# UART0 register map
Vendor: Texas Instruments
Peripheral module from a debugger description file (folder UCD3138R064RSM).
Registers are 32-bit, access per field, no defined reset value unless marked. A register's access mark holds for its fields unless they carry their own. Offsets are as the file gives them; lines under a group give offsets from that group; [hi:lo] are bit positions; {n}, {i} and the like mark numbered series; 'fields as' and 'values as' point back to an identical list; <NAME> marks a mode.

## UART0
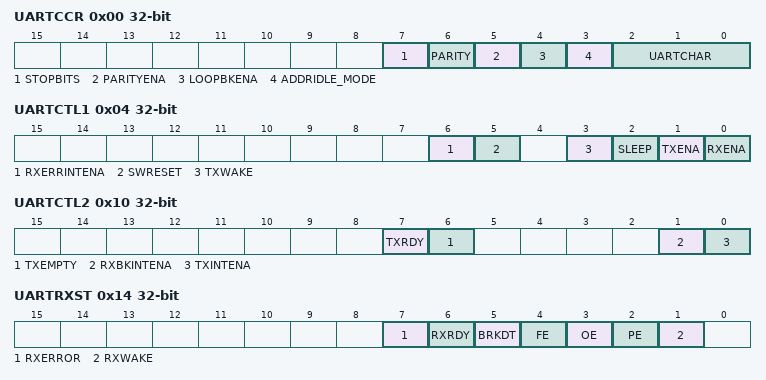
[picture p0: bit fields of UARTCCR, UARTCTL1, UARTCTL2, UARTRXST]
0x00 UARTCCR — UARTCCR defines the character format, protocol, and communications mode used by the UART.
  [7] STOPBITS rw — UART number of stop bits. #br#This bit specifies the number of stop bits transmitted. The receiver checks for only one stop bit.
    0=STOPBITS_ONE (One stop bit); 1=STOPBITS_TWO (Two stop bits)
  [6] PARITY rw — UART parity odd/even selection. #br#If the PARITY ENABLE bit (UARTCCR, bit 5) is set, PARITY (bit 6) designates odd or even parity (odd or even number of bits with the value of 1 in both transmitted and received characters).
    0=PARITY_ODD (Odd parity); 1=PARITY_EVEN (Even parity)
  [5] PARITYENA rw — UART parity enable. #br#This bit enables or disables the parity function. If the UART is in the addressbit multiprocessor mode (set using bit 3 of this register), the address bit is included in the parity calculation (if parity is enabled). For characters of less than eight bits, the remaining unused bits should be masked out of the parity calculation.
    0=PARITYENA_DISABLE (Parity disabled; no parity bit is generated during transmission or is expected during reception); 1=PARITYENA_ENABLE (Parity is enabled)
  [4] LOOPBKENA rw — Loop Back test mode enable. #br#This bit enables the Loop Back test mode where the Tx pin is internally connected to the Rx pin.
    0=LOOPBKENA_DISABLE (Loop Back test mode disabled); 1=LOOPBKENA_ENABLE (Loop Back test mode enabled)
  [3] ADDRIDLE_MODE rw — UART multiprocessor mode control bit. #br# #br#This bit selects one of the multiprocessor protocols.Multiprocessor communication is different from the other communication modes because it uses SLEEP and TXWAKE functions (bits UARTCTL1, bit 2 and UARTCTL1, bit 3, respectively). The idle-line mode is usually used for normal communications because the address-bit mode #br#adds an extra bit to the frame. The idle-line mode does not add this extra bit and is compatible with RS-232 type communications.
    0=ADDRIDLE_MODE_IDLE (Idle-line mode protocol selected); 1=ADDRIDLE_MODE_ADDRBIT (Address-bit mode protocol selected)
  [2:0] UARTCHAR rw — Character-length control bits 2-0. #br# #br#These bits select the UART character length from one to eight bits. Characters of less than eight bits are right-justified in UARTRXBUF and UARTRXEMU and are padded with leading zeros in UARTRXBUF. UARTTXBUF doesn't need to be padded with leading zeros.
    {v}=UARTCHAR_LENGTH_{v+1} (v=0..7)
0x04 UARTCTL1 — UARTCTL1 controls the receiver/transmitter enable, TXWAKE and SLEEP functions, and the UART software reset.
  [6] RXERRINTENA rw — UART receive error interrupt enable. #br#Setting this bit enables an interrupt if the RX ERROR bit (UARTRXST, bit 7) becomes set because of errors occurring.
    0=RXERRINTENA_DISABLE (Receive error interrupt disabled); 1=RXERRINTENA_ENABLE (Receive error interrupt enabled)
  [5] SWRESET rw — UART software reset (active low). #br#Writing a 0 to this bit initializes the UART state machines and operating flags (registers UARTCTL2 and UARTRXST) to the reset condition. This reset will not reset the FIFO pointers or flush out the data in TX/RX FIFO. If you need to clear the FIFO then perform SWRESET + TXFFINT + RXFFINT or refer to a channel reset UARTFFTX[UARTRST]. #br# #br#The SW RESET bit does not affect any of the configuration bits. All affected logic is held in the specified reset state until a 1 is written to SW RESET (the bit values following a reset are shown beneath each register diagram in this section). Thus, after a system reset, re-enable the UART by writing a 1 to this bit. Clear this bit after a receiver break detect (BRKDT flag, bit UARTRXST, bit 5). #br# #br#SW RESET affects the operating flags of the UART, but it neither affects the configuration bits nor restores the reset values. Once SW RESET is asserted, the flags are frozen until the bit is deasserted. #br#The affected flags are as follows: #br# #br#Value After SW UART Flag Register Bit #br#RESET #br#1 TXRDY UARTCTL2, bit 7 #br#1 TX EMPTY UARTCTL2, bit 6 #br#0 RXWAKE UARTRXST, bit 1 #br#0 PE UARTRXST, bit 2 #br#0 OE UARTRXST, bit 3 #br#0 FE UARTRXST, bit 4 #br#0 BRKDT UARTRXST, bit 5 #br#0 RXRDY UARTRXST, bit 6 #br#0 RX ERROR UARTRXST, bit 7
    0=SWRESET_RESET (Writing a 0 to this bit initializes the UART state machines and operating flags (registers UARTCTL2 and UARTRXST) to the reset condition.); 1=SWRESET_REEN (After a system reset, re-enable the UART by writing a 1 to this bit. There is no time requirement to meet before writing a one to this bit after writing a zero.)
  [3] TXWAKE rw — UART transmitter wake-up method select. #br# #br#The TXWAKE bit controls selection of the data-transmit feature, depending on which transmit mode (idle-line or address-bit) is specified at the ADDR/IDLE MODE bit (UARTCCR, bit 3)
    0=TXWAKE_NOSELECT (Transmit feature is not selected. In idle-line mode: write a 1 to TXWAKE, then write data to register UARTTXBUF to generate an idle period of 11 data bits In address-bit mode: write a 1 to TXWAKE, then write data to UARTTXBUF to set the address bit for that frame to 1); 1=TXWAKE_SELECT (Transmit feature selected is dependent on the mode, idle-line or address-bit: TXWAKE is not cleared by the SW RESET bit (UARTCTL1, bit 5); it is cleared by a system reset or the transfer of TXWAKE to the WUT flag.)
  [2] SLEEP rw — UART sleep. #br#The TXWAKE bit controls selection of the data-transmit feature, depending on which transmit mode (idle-line or address-bit) is specified at the ADDR/IDLE MODE bit (UARTCCR, bit 3). In a multiprocessor configuration, this bit controls the receiver sleep function. Clearing this bit brings the UART out of the sleep mode. #br# #br#The receiver still operates when the SLEEP bit is set; however, operation does not update the receiver buffer ready bit (UARTRXST, bit 6, RXRDY) or the error status bits (UARTRXST, bit 5-2: BRKDT, FE, OE, and PE) unless the address byte is detected. SLEEP is not cleared when the address byte is detected.
    0=SLEEP_DISABLE (Sleep mode disabled); 1=SLEEP_ENABLE (Sleep mode enabled)
  [1] TXENA rw — UART transmitter enable. #br#Data is transmitted through the UARTTXD pin only when TXENA is set. If reset, transmission is halted but only after all data previously written to UARTTXBUF has been sent. Data written into UARTTXBUF when TXENA is disabled will not be transmitted even if the TXENA is enabled later.
    0=TXENA_DISABLE (Transmitter disabled); 1=TXENA_ENABLE (Transmitter enabled)
  [0] RXENA rw — UART receiver enable. #br#Data is received on the UARTRXD pin and is sent to the receiver shift register and then the receiver buffers. This bit enables or disables the receiver (transfer to the buffers). #br#Clearing RXENA stops received characters from being transferred to the two receiver buffers and also stops the generation of receiver interrupts. However, this will not stop RX errors from triggering interrupts. To disable interrupts from RX errors use the RXERRINTENA bit. To stop propagation of the BRKDT interrupt use the RXBKINTENA bit. #br# #br#The receiver shift register can continue to assemble characters even while RXENA is cleared. Thus, if RXENA is set during the reception of a character, the complete character will be transferred into the receiver buffer registers, UARTRXEMU and UARTRXBUF.
    0=RXENA_DISABLE (Prevent received characters from transfer into the UARTRXEMU and UARTRXBUF receiver buffers); 1=RXENA_ENABLE (Send received characters to UARTRXEMU and UARTRXBUF)
0x08 UARTHBAUD — The values in UARTHBAUD and UARTLBAUD specify the baud rate for the UART.
  [7:0] BAUD rw — UART 16-bit baud selection Registers UARTHBAUD (MSbyte). #br# #br#The internally-generated serial clock is determined by the low speed peripheral clock (LSPCLK) signal and the two baud-select registers. The UART uses the 16-bit value of these registers to select one of 64K serial clock rates for the communication modes. #br# #br#BRR = (UARTHBAUD << 8) + (UARTLBAUD) #br# #br#The UART baud rate is calculated using the following equation: #br# #br#UART Asynchronous Baud = LSPCLK / ((BRR + 1) *8) #br# #br#Alternatively, #br# #br#BRR = LSPCLK / (UART Asynchronous Baud * 8) - 1 #br# #br#Note that the above formulas are applicable only when 0 < BRR < 65536. If BRR = 0, then #br# #br#UART Asynchronous Baud = LSPCLK / 16 #br# #br#Where: BRR = the 16-bit value (in decimal) in the baud-select registers
0x0C UARTLBAUD — The values in UARTHBAUD and UARTLBAUD specify the baud rate for the UART.
  [7:0] BAUD rw — See UARTHBAUD Detailed Description
0x10 UARTCTL2 — UARTCTL2 enables the receive-ready, break-detect, and transmit-ready interrupts as well as transmitter-ready and -empty flags.
  [7] TXRDY ro — Transmitter buffer register ready flag. #br#When set, this bit indicates that the transmit data buffer register, UARTTXBUF, is ready to receive another character. Writing data to the UARTTXBUF automatically clears this bit. When set, this flag asserts a transmitter interrupt request if the interrupt-enable bit, TX INT ENA (UARTCTL2.0), is also set. TXRDY is set to 1 by enabling the SW RESET bit (UARTCTL1.5) or by a system reset.
    0=TXRDY_FULL (UARTTXBUF is full); 1=TXRDY_READY (UARTTXBUF is ready to receive the next character)
  [6] TXEMPTY ro — Transmitter empty flag. #br#This flag's value indicates the contents of the transmitter's buffer register (UARTTXBUF) and shift register (TXSHF). An active SW RESET (UARTCTL1.5), or a system reset, sets this bit. This bit does not cause an interrupt request.
    0=TXEMPTY_LOAD (Transmitter buffer or shift register or both are loaded with data); 1=TXEMPTY_EMPTY (Transmitter buffer and shift registers are both empty)
  [1] RXBKINTENA rw — Receiver-buffer/break interrupt enable. #br#This bit controls the interrupt request caused by either the RXRDY flag or the BRKDT flag (bits UARTRXST.6 and .5) being set. However, RX/BK INT ENA does not prevent the setting of these flags.
    0=RXBKINTENA_DISABLE (Disable RXRDY/BRKDT interrupt); 1=RXBKINTENA_ENABLE (Enable RXRDY/BRKDT interrupt)
  [0] TXINTENA rw — UARTTXBUF-register interrupt enable. #br#This bit controls the interrupt request caused by the setting of TXRDY flag bit (UARTCTL2.7). However, it does not prevent the TXRDY flag from being set (which indicates UARTTXBUF is ready to receive another character). #br# #br#0 Disable TXRDY interrupt #br#1 Enable TXRDY interrupt. #br# #br#In non-FIFO mode, a dummy (or a valid) data has to be written to UARTTXBUF for the first transmit interrupt to occur. This is the case when you enable the transmit interrupt for the first time and also when you re-enable (disable and then enable) the transmit interrupt. If TXINTENA is enabled after writing the data to UARTTXBUF, it will not generate an interrupt.
    0=TXINTENA_DISABLE (Disable TXRDY interrupt); 1=TXINTENA_ENABLE (Enable TXRDY interrupt)
0x14 UARTRXST ro — UARTRXST contains seven bits that are receiver status flags (two of which can generate interrupt requests). Each time a complete character is transferred to the receiver buffers (UARTRXEMU and UARTRXBUF), the status flags are updated.
  [7] RXERROR — UART receiver error flag. #br#The RX ERROR flag indicates that one of the error flags in the receiver status register is set. RX ERROR is a logical OR of the break detect, framing error, overrun, and parity error enable flags (bits 5-2: BRKDT, FE, OE, and PE). #br#A 1 on this bit will cause an interrupt if the RX ERR INT ENA bit (UARTCTL1.6) is set. This bit can be used for fast error-condition checking during the interrupt service routine. This error flag cannot be cleared directly; it is cleared by an active SW RESET, channel reset (UARTRST), or by a system reset. #br# #br#Note: UART Module Interrupt Reaction Time - Occasional BRKDT or other errors such as FE/PE being triggered could occur if there are tight timings occurring in the application. #br# #br#Interrupts are not triggered until approximately 7/8 of the stop bit has been detected (~0.875 bit time). Actual value of this delay before ISR entry is: ((7*BAUD_CLK_PERIOD)/8+3*SYSCLK_PERIOD). #br# #br#The UART will not begin reading additional bits/characters until the RX ISR completes so it is critical to complete the ISR before the next byte's start bit begins. This leaves approximately 1/8 bit time (~0.125 bit time) to complete the entire ISR, regardless of interrupt cause. #br# #br#If the ISR is not completed before the beginning of the next start bit (before the RX line goes low again), the UART module will begin reading the start bit late in the wrong location and therefore may read all bits incorrectly until the next correctly aligned start bit (when ISR has sufficient time to process before a start bit again). #br# #br#Recommended methods for avoiding errors (to accommodate for the 0.875 bit time required for ISR to begin): #br#1. Keep the RX ISR short. The RX ISR should only be used to move data in the FIFO/buffer into memory where it can be processed in another, less time-critical function. #br#2. Avoid excessive nesting of other interrupts within the UART RX ISR. Do not allow the nesting to delay UART RX ISR completion past the ~0.125 bit time window allowed. #br#3. If additional time (more than the ~0.125 bit time) is required, delay can be added in the other device's firmware before transmitting additional data to the C2000 device's UART RX pin. Delays can be added to the other device as follows: #br# A. Sending bytes with 2 stop bits to the C2000 device provides ~1.125 bit time of processing time for C2000 RX ISR to complete. #br# B. Adding manual delay in the firmware of the other device transmitting to the C2000 device after every BYTE transmitted will provide (delay + ~0.125 bit time) processing time for the C2000 RX ISR to complete. #br# C. Adding manual delay in the firmware of the other device transmitting to the C2000 device after every C2000 RX INTERRUPT occurs will provide (delay + ~0.125 bit time) processing time for the C2000 RX ISR to complete. This is more difficult to implement as it requires the other device to predict when its transmitted data will trigger an RX interrupt on the C2000 device. Examples of things that can trigger an RX interrupt are RX-FIFO level being reached, BRKDT being sent, RXERROR occurring, etc.
    0=RXERROR_NO_ERR (No error flags set); 1=RXERROR_SET_ERR (Error flag(s) set)
  [6] RXRDY — UART receiver-ready flag. #br#When a new character is ready to be read from the UARTRXBUF register, the receiver sets this bit, and a receiver interrupt is generated if the RX/BK INT ENA bit (UARTCTL2.1) is a 1. RXRDY is cleared by a reading of the UARTRXBUF register, by an active SW RESET, channel reset (UARTRST), or by a system reset.
    0=RXRDY_NO_CHAR (No new character in UARTRXBUF); 1=RXRDY_READY (Character ready to be read from UARTRXBUF)
  [5] BRKDT — UART break-detect flag. #br#The UART sets this bit when a break condition occurs. A break condition occurs when the UART receiver data line (UARTRXD) remains continuously low for at least 9.625 bits, beginning after a missing first stop bit. If the UARTRX line goes high at any point during the 9.625 bits then the UART will not flag a break detect. In order to trigger the first stop bit missed, the typical method is to hold the RX line low for 1 start bit, 8 data bits, 1 optional address bit, 1 optional parity bit, 1 stop bit, and 9.625 bits of additional time held low. This is a total of 19.625 (no parity/address bit), 20.625 (either parity or address bit), or 21.625 (both parity and address bit) bit times. #br# #br#To instead detect a "break seq" or "break sequence" of 11 bits of low voltage level (0), ISR code can use the following combination of flags and received data: FE==1 && PE==1 && UARTRXBUF.SAR (received character)==0x00. This assumes parity enabled and odd parity set. With even parity, PE==0 instead. The detection of 11 bits of low/0 can be reduced to 10 bits of low if no parity bit is used (then PE flag does not matter to detect the sequence). #br# #br#The occurrence of a break causes a receiver interrupt to be generated if the RX/BK INT ENA bit is a 1, but it does not cause the receiver buffer to be loaded. #br# #br#A BRKDT interrupt can occur even if the receiver SLEEP bit is set to 1. #br# #br#BRKDT is cleared by an active SW RESET, UARTRST bit, or by a system reset. It is not cleared by receipt of a character after the break is detected. #br# #br#If Break Detect (BRKDT) is set, then RXRDY won't be set and there will be no further interrupts after the first interrupt where there is an error detected if a SW reset, channel reset, or system reset is not performed. In order to receive more characters, the UART must be reset by toggling the SW RESET bit, channel reset (UARTRST), or by a system reset. #br# #br#NOTE: If your system is susceptible to break detects, ensure that you have a pull-up resistor on the UART-RX pin to provide proper return-to-high signal behavior and noise immunity. #br# #br#NOTE: To monitor a break detect, place an oscilloscope on the C2000 UART-RX line and monitor for a low-signal greater than 9.625 bits wide. If this is found and a break is not expected, please correct the software in the other device that is transmitting to this C2000 device. There should never be a low-signal greater than 9.625 bits wide on the UART-RX line of the C2000 device unless a break detect is being transmitted purposely.
    0=BRKDT_NO_CODT (No break condition); 1=BRKDT_CODT (Break condition occurred)
  [4] FE — UART framing-error flag. #br#The UART sets this bit when an expected stop bit is not found. Only the first stop bit is checked. The missing stop bit indicates that synchronization with the start bit has been lost and that the character is incorrectly framed. The FE bit is reset by a clearing of the SW RESET bit, channel reset (UARTRST), or by a system reset. NOTE: FE will be flagged prior to BRKDT, except when RX is in sleep mode. In sleep mode, when there is no RX WAKEUP and RXD line is low for greater than 10 bits, BRKDT will be flagged while FE will not be flagged.
    0=FE_NO_DETCT (No framing error detected); 1=FE_ERR_DETCT (Framing error detected)
  [3] OE — UART overrun-error flag. #br#The UART sets this bit when a character is transferred into registers UARTRXEMU and UARTRXBUF before the previous character is fully read by the CPU or DMAC. The previous character is overwritten and lost. The OE flag bit is reset by an active SW RESET, channel reset (UARTRST), or a system reset.
    0=OE_NO_DETCT (No overrun error detected); 1=OE_ERR_DETCT (Overrun error detected)
  [2] PE — UART parity-error flag. #br#This flag bit is set when a character is received with a mismatch between the number of 1s and its parity bit. The address bit is included in the calculation. If parity generation and detection is not enabled, the PE flag is disabled and read as 0. The PE bit is reset by an active SW RESET, channel reset (UARTRST), or a system reset.
    0=PE_NO_ERR (No parity error or parity is disabled); 1=PE_ERR_DETCT (Parity error is detected)
  [1] RXWAKE — Receiver wake-up-detect flag
    0=REWAKE_NO_DETCT (No detection of a receiver wake-up condition); 1=REWAKE_DETCT (A value of 1 in this bit indicates detection of a receiver wake-up condition. In the address-bit multiprocessor mode (UARTCCR.3 = 1), RXWAKE reflects the value of the address bit for the character contained in UARTRXBUF. In the idle-line multiprocessor mode, RXWAKE is set if the UARTRXD data line is detected as idle. RXWAKE is a read-only flag, cleared by one of the following: #br# #br#- The transfer of the first byte after the address byte to UARTRXBUF (only in non-FIFO mode) #br#- The reading of UARTRXBUF #br#- An active SW RESET #br#- Channel reset (UARTRST) #br#- A system reset)
0x18 UARTRXEMU ro — Normal UART data-receive operations read the data received from the UARTRXBUF register. The UARTRXEMU register is used principally by the emulator (EMU) because it can continuously read the data received for screen updates without clearing the RXRDY flag. UARTRXEMU is cleared by a system reset. This is the register that should be used in an emulator watch window to view the contents of the UARTRXBUF register. UARTRXEMU is not physically implemented; it is just a different address location to access the UARTRXBUF register without clearing the RXRDY flag.
  [7:0] ERXDT — Receive emulation buffer data
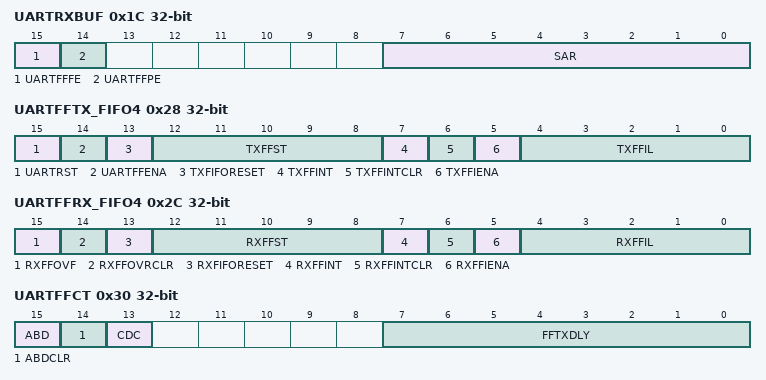
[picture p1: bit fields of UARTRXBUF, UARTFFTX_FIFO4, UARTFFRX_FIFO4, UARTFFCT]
0x1C UARTRXBUF ro — When the current data received is shifted from RXSHF to the receiver buffer, flag bit RXRDY is set and the data is ready to be read. If the RXBKINTENA bit (UARTCTL2.1) is set, this shift also causes an interrupt. When UARTRXBUF is read, the RXRDY flag is reset. UARTRXBUF is cleared by a system reset.
  [15] UARTFFFE — UARTFFFE. UART FIFO Framing error flag bit (applicable only if the FIFO is enabled) #br# #br#Note: 'UARTFFFE' is meant to serve as a flag for the specific set of data being received/read in the UARTRXBUF register. Each set of data received into the FIFO will have this information. The 'FE' bit within the UARTRXST register can be thought off as high level error flag where the flag will get set if any data that has been received has a framing error.
    0=UARTFFPE_NO_ERR (No frame error occurred while receiving the character, in bits 7-0. This bit is associated with the character on the top of the FIFO.); 1=UARTFFPE_ERR_OCCR (A frame error occurred while receiving the character in bits 7-0. This bit is associated with the character on the top of the FIFO.)
  [14] UARTFFPE — UARTFFPE. UART FIFO parity error flag bit (applicable only if the FIFO is enabled) #br# #br#Note: 'UARTFFPE' is meant to serve as a flag for the specific set of data being received/read in the UARTRXBUF register. Each set of data received into the FIFO will have this information. The 'PE' bit within the UARTRXST register can be thought off as high level error flag where the flag will get set if any data that has been received has a parity error. #br# #br#Note: If the parity is changed in the middle of data reception, the UART module will not reinterpret the data with the new parity or other settings that may have changed. Therefore, changing the parameter, the FIFO should be cleared or the user should acknowledge that there will most likely be errors in the data caused by the change. #br# #br#Note: If RX parity errors are occurring intermittently this could be due to the length of the UART ISR. To help prevent this, ensure that interrupt nesting is limited, increase the UART interrupt priority, and move as much of the processing as possible out of the ISR (to reduce ISR time to the absolute minimum).
    0=UARTFFFE_NO_ERR (No parity error occurred while receiving the character, in bits 7-0. This bit is associated with the character on the top of the FIFO.); 1=UARTFFFE_ERR_OCCR (A parity error occurred while receiving the character in bits 7-0. This bit is associated with the character on the top of the FIFO.)
  [7:0] SAR — Receive Character bits
0x24 UARTTXBUF — Data bits to be transmitted are written to UARTTXBUF. These bits must be rightjustified because the leftmost bits are ignored for characters less than eight bits long. The transfer of data from this register to the TXSHF transmitter shift register sets the TXRDY flag (UARTCTL2.7), indicating that UARTTXBUF is ready to receive another set of data. If bit TXINTENA (UARTCTL2.0) is set, this data transfer also causes an interrupt.
  [7:0] TXDT rw — Transmit data buffer
0x28 UARTFFTX_FIFO4 — UARTFFTX controls the transmit FIFO interrupt, FIFO enhancements, and reset for the UART transmit and receive channels.
  [15] UARTRST rw — UART Reset #br#0 A write of 0 will cause a SW RESET + a RESET of TXFFINT and RXFFINT, essentially clearing TX/RX FIFO content. The UART will be held in reset until a write of 1. Additionally it resets the RXFFOVF, PE, OE, FE, RXERROR, BRKDET, RXRDY, and RXWAKE flags. It will also set TXRDY and TXEMPTY bits as 1. #br#1 UART FIFO can resume transmit or receive. UARTRST should be 1 even for Autobaud logic to work.
  [14] UARTFFENA rw — UART FIFO enable
    0=UARTFFENA_DISABLE (UART FIFO enhancements are disabled); 1=UARTFFENA_ENABLE (UART FIFO enhancements are enabled)
  [13] TXFIFORESET rw — Transmit FIFO reset
    0=TXFIFOXRESET_RESET (Reset the FIFO pointer to zero and hold in reset); 1=TXFIFOXRESET_REEN (Re-enable transmit FIFO operation)
  [12:8] TXFFST ro — FIFO status
    0=TXFFST_EMPTY (Transmit FIFO is empty); {v}=TXFFST_WORD{v} (Transmit FIFO has {v} words) (v=1..4)
  [7] TXFFINT ro — Transmit FIFO interrupt
    0=TXFFINT_NO_OCCR (TXFIFO interrupt has not occurred, read-only bit); 1=TXFFINT_OCCR (TXFIFO interrupt has occurred, read-only bit)
  [6] TXFFINTCLR rw — Transmit FIFO clear
    0=TXFFINTCLR_NO_EFFECT (Write 0 has no effect on TXFIFINT flag bit, Bit reads back a zero); 1=TXFFINTCLR_CLR (Write 1 to clear TXFFINT flag in bit 7)
  [5] TXFFIENA rw — Transmit FIFO interrrupt enable
    0=TXFFIENA_DISABLE (TX FIFO interrupt is disabled); 1=TXFFIENA_ENABLE (TX FIFO interrupt is enabled. This interrupt is triggered whenever the transmit FIFO status (TXFFST) bits match (equal to or less than) the interrupt trigger level bits TXFFIL (bits 4-0).)
  [4:0] TXFFIL rw — TXFFIL4-0 Transmit FIFO interrupt level bits. #br# #br#The transmit FIFO generates an interrupt whenever the FIFO status bits (TXFFST4-0) are less than or equal to the FIFO level bits (TXFFIL4-0). The maximum value that can be assigned to these bits to generate an interrupt cannot be more than the depth of the TX FIFO. The default value of these bits after reset is 00000b. Users should set TXFFIL to best fit their application needs by weighing between the CPU overhead to service the ISR and the best possible usage of UART bus bandwidth.
0x2C UARTFFRX_FIFO4 — UARTFFRX controls the receive FIFO interrupt, receive FIFO reset, and status of the receive FIFO overflow.
  [15] RXFFOVF ro — Receive FIFO overflow. #br#This will function as flag, but cannot generate interrupt by itself. This condition will occur while receive interrupt is active. Receive interrupts should service this flag condition.
    0=RXFFOVF_NO_OVF (Receive FIFO has not overflowed, read-only bit); 1=RXFFOVF_OVF (Receive FIFO has overflowed, read-only bit. More than 16 words have been received in to the FIFO, and the first received word is lost)
  [14] RXFFOVRCLR rw — RXFFOVF clear #br#Note: Both RXFFIL and RXFFOVF flags are ORed together, so they need to be cleared at the same time (RXFFINTCLR & RXFFOVRCLR) during overflow scenarios else it will prevent further interrupts from occurring.
    0=RXFFOVRCLR_NO_EFFECT (Write 0 has no effect on RXFFOVF flag bit, Bit reads back a zero); 1=RXFFOVRCLR_CLR (Write 1 to clear RXFFOVF flag in bit 15)
  [13] RXFIFORESET rw — Receive FIFO reset
    0=RXFIFORESET_RESET (Write 0 to reset the FIFO pointer to zero, and hold in reset.); 1=RXFIFORESET_REEN (Re-enable receive FIFO operation)
  [12:8] RXFFST ro — FIFO status
    0=RXFFST_EMPTY (Receive FIFO is empty); {v}=RXFFST_WORD{v} (Receive FIFO has {v} words) (v=1..4)
  [7] RXFFINT ro — Receive FIFO interrupt
    0=RXFFINT_NO_OCCR (RXFIFO interrupt has not occurred, read-only bit); 1=RXFFINT_OCCR (RXFIFO interrupt has occurred, read-only bit)
  [6] RXFFINTCLR wo — Receive FIFO interrupt clear #br#Note: Both RXFFIL and RXFFOVF flags are ORed together, so they need to be cleared at the same time (RXFFINTCLR & RXFFOVRCLR) during overflow scenarios else it will prevent further interrupts from occurring.
    0=RXFFINTCLR_NO_EFFECT (Write 0 has no effect on RXFIFINT flag bit. Bit reads back a zero.); 1=RXFFINTCLR_CLR (Write 1 to clear RXFFINT flag in bit 7)
  [5] RXFFIENA rw — Receive FIFO interrupt enable
    0=RXFFIENA_DISABLE (RX FIFO interrupt is disabled); 1=RXFFIENA_ENABLE (RX FIFO interrupt is enabled. This interrupt is triggered whenever the receive FIFO status (RXFFST) bits match (equal to or greater than) the interrupt trigger level bits RXFFIL (bits 4-0).)
  [4:0] RXFFIL rw — Receive FIFO interrupt level bits #br# #br#The receive FIFO generates an interrupt whenever the FIFO status bits (RXFFST4-0) are greater than or equal to the FIFO level bits (RXFFIL4-0). The maximum value that can be assigned to these bits to generate an interrupt cannot be more than the depth of the RX FIFO. The default value of these bits after reset is 11111b. Users should set RXFFIL to best fit their application needs by weighing between the CPU overhead to service the ISR and the best possible usage of received UART data.
0x30 UARTFFCT — UARTFFCT contains the status of auto-baud detect, clears the auto-baud flag, and calibrate for A-detect bit.
  [15] ABD ro — Auto-baud detect (ABD) bit
    0=ADB_NO_COMPLT (Auto-baud detection is not complete. "A","a" character has not been received successfully.); 1=ADB_COMPLT (Auto-baud hardware has detected "A" or "a" character on the UART receive register. Auto-detect is #br#complete.)
  [14] ABDCLR wo — ABD-clear bit
    0=ABDCLR_NO_EFFECT (Write 0 has no effect on ABD flag bit. Bit reads back a zero.); 1=ABDCLR_CLR (Write 1 to clear ABD flag in bit 15.)
  [13] CDC rw — CDC calibrate A-detect bit
    0=CDC_DISABLE (Disables auto-baud alignment); 1=CDC_ENABLE (Enables auto-baud alignment)
  [7:0] FFTXDLY rw — FIFO transfer delay. These bits define the delay between every transfer from FIFO transmit bufferto transmit shift register. The delay is defined in the number of UART serial baud clock cycles. The 8 bit register could define a minimum delay of 0 baud clock cycles and a maximum of 256 baud clock cycles #br# #br#In FIFO mode, the buffer (TXBUF) between the shift register and the FIFO should be filled only after the shift register has completed shifting of the last bit. This is required to pass on the delay between transfers to the data stream. In FIFO mode, TXBUF should not be treated as one additional level of buffer. The delayed transmit feature will help to create an auto-flow scheme without RTS/CTS controls as in standard UARTS. #br# #br#When UART is configured for one stop-bit, delay introduced by FFTXDLY between one frame and the next frame is equal to number of baud clock cycles that FFTXDLY is set to. #br# #br#When UART is configured for two stop-bits, delay introduced by FFTXDLY between one frame and the next frame is equal to number of baud clock cycles that FFTXDLY is set to minus 1.
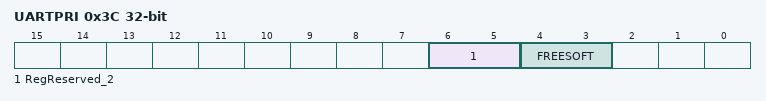
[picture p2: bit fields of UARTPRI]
0x3C UARTPRI — UARTPRI determines what happens when an emulation suspend event occurs.
  [6:5] RegReserved_2 rw — Reserved
  [4:3] FREESOFT rw — These bits determine what occurs when an emulation suspend event occurs (for example, when the debugger hits a breakpoint). The peripheral can continue whatever it is doing (free-run mode), or if in stop mode, it can either stop immediately or stop when the current operation (the current receive/transmit sequence) is complete.
    0=FREE_SOFT_HARDSTOP (Immediate stop on suspend); 1=FREE_SOFT_SOFTSTOP (Complete current receive/transmit sequence before stopping); 2=FREE_SOFT_FREERUN1 (Free run); 3=FREE_SOFT_FREERUN2 (Free run)
0x40 LOSPCP — Low Speed Clock Source Prescalar
  [2:0] LSPCLKDIV rw — These bits configure the low-speed peripheral clock (LSPCLK) rate.
    0=DIV_by_1 (LSPCLK = / 1); 1=DIV_by_2 (LSPCLK = / 2); 2=DIV_by_4 (LSPCLK = / 4 (default on reset)); 3=DIV_by_6 (LSPCLK = / 6); 4=DIV_by_8 (LSPCLK = / 8); 5=DIV_by_10 (LSPCLK = / 10); 6=DIV_by_12 (LSPCLK = / 12); 7=DIV_by_14 (LSPCLK = / 14)
